# nrf52810 register map
Vendor: Nordic Semiconductor; Series: nrf52; File version: 1
CPU: CM4 r0p1, little endian, MPU, no FPU, 3 interrupt priority bits
Registers are 32-bit, read-write, reset 0x0 unless marked. A register's access mark holds for its fields unless they carry their own. Offsets are from the block's base; [hi:lo] are bit positions; {n}, {i} and the like mark numbered series; 'fields as' and 'values as' point back to an identical list; <NAME> marks a mode.

## COMP — Comparator
Base 0x40013000
0x00 TASKS_START wo — Start comparator
  [0] TASKS_START
    1=Trigger task
0x04 TASKS_STOP wo — Stop comparator
  [0] TASKS_STOP
    1=Trigger task
0x08 TASKS_SAMPLE wo — Sample comparator value
  [0] TASKS_SAMPLE
    1=Trigger task
0x100 EVENTS_READY — COMP is ready and output is valid
  [0] EVENTS_READY
    0=NotGenerated (Event not generated); 1=Generated (Event generated)
0x104 EVENTS_DOWN — Downward crossing
  [0] EVENTS_DOWN
    values as EVENTS_READY.EVENTS_READY
0x108 EVENTS_UP — Upward crossing
  [0] EVENTS_UP
    values as EVENTS_READY.EVENTS_READY
0x10C EVENTS_CROSS — Downward or upward crossing
  [0] EVENTS_CROSS
    values as EVENTS_READY.EVENTS_READY
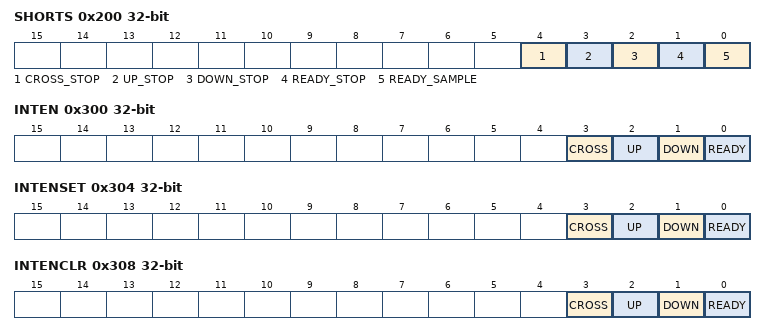
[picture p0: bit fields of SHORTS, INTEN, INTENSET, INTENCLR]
0x200 SHORTS — Shortcuts between local events and tasks
  [all] fields
    0=Disabled (Disable shortcut); 1=Enabled (Enable shortcut)
  [4] CROSS_STOP — Shortcut between event CROSS and task STOP
  [3] UP_STOP — Shortcut between event UP and task STOP
  [2] DOWN_STOP — Shortcut between event DOWN and task STOP
  [1] READY_STOP — Shortcut between event READY and task STOP
  [0] READY_SAMPLE — Shortcut between event READY and task SAMPLE
0x300 INTEN — Enable or disable interrupt
  [all] fields
    0=Disabled; 1=Enabled
  [3] CROSS — Enable or disable interrupt for event CROSS
  [2] UP — Enable or disable interrupt for event UP
  [1] DOWN — Enable or disable interrupt for event DOWN
  [0] READY — Enable or disable interrupt for event READY
0x304 INTENSET — Enable interrupt
  [all] fields
    on read: 0=Disabled (Read: Disabled); 1=Enabled (Read: Enabled) | on write: 1=Set (Enable)
  [3] CROSS — Write '1' to enable interrupt for event CROSS
  [2] UP — Write '1' to enable interrupt for event UP
  [1] DOWN — Write '1' to enable interrupt for event DOWN
  [0] READY — Write '1' to enable interrupt for event READY
0x308 INTENCLR — Disable interrupt
  [all] fields
    on read: 0=Disabled (Read: Disabled); 1=Enabled (Read: Enabled) | on write: 1=Clear (Disable)
  [3] CROSS — Write '1' to disable interrupt for event CROSS
  [2] UP — Write '1' to disable interrupt for event UP
  [1] DOWN — Write '1' to disable interrupt for event DOWN
  [0] READY — Write '1' to disable interrupt for event READY
0x400 RESULT ro — Compare result
  [0] RESULT — Result of last compare. Decision point SAMPLE task.
    0=Below (Input voltage is below the threshold (VIN+ < VIN-)); 1=Above (Input voltage is above the threshold (VIN+ > VIN-))
0x500 ENABLE — COMP enable
  [1:0] ENABLE — Enable or disable COMP
    0=Disabled; 2=Enabled
0x504 PSEL — Pin select
  [2:0] PSEL — Analog pin select
    {v}=AnalogInput{v} (AIN{v} selected as analog input) (v=0..6); 7=VddDiv2 (VDD/2 selected as analog input)
0x508 REFSEL reset 0x4 — Reference source select for single-ended mode
  [2:0] REFSEL — Reference select
    0=Int1V2 (VREF = internal 1.2 V reference (VDD >= 1.7 V)); 1=Int1V8 (VREF = internal 1.8 V reference (VDD >= VREF + 0.2 V)); 2=Int2V4 (VREF = internal 2.4 V reference (VDD >= VREF + 0.2 V)); 4=VDD (VREF = VDD); 5=ARef (VREF = AREF (VDD >= VREF >= AREFMIN))
0x50C EXTREFSEL — External reference select
  [2:0] EXTREFSEL — External analog reference select
    {v}=AnalogReference{v} (Use AIN{v} as external analog reference) (v=0..7)
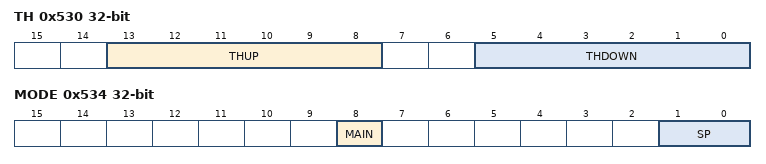
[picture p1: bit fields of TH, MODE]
0x530 TH — Threshold configuration for hysteresis unit
  [13:8] THUP — VUP = (THUP+1)/64*VREF
  [5:0] THDOWN — VDOWN = (THDOWN+1)/64*VREF
0x534 MODE — Mode configuration
  [8] MAIN — Main operation modes
    0=SE (Single-ended mode); 1=Differential mode
  [1:0] SP — Speed and power modes
    0=Low (Low-power mode); 1=Normal mode; 2=High-speed mode
0x538 HYST — Comparator hysteresis enable
  [0] HYST — Comparator hysteresis
    0=NoHyst (Comparator hysteresis disabled); 1=Hyst50mV (Comparator hysteresis enabled)
